VERSION ""

NS_ :

BS_:

BU_: Inverter

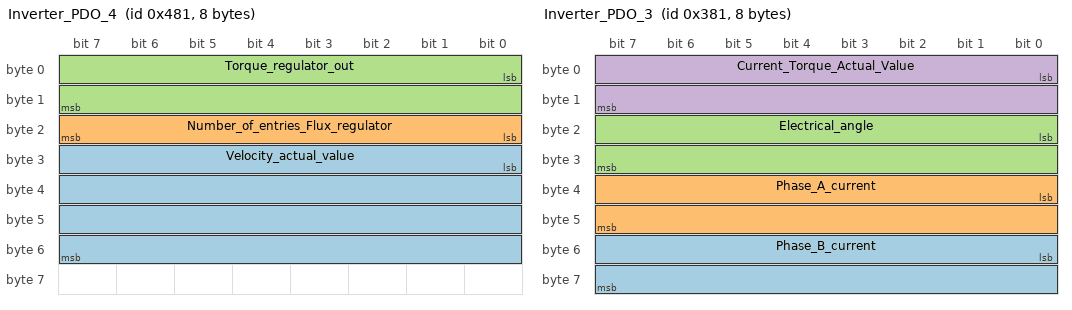
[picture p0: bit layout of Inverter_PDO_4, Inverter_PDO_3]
BO_ 1153 Inverter_PDO_4: 8 Vector__XXX
 SG_ Velocity_actual_value : 24|32@1- (1,0) [-2147483648|2147483647] "" Vector__XXX
 SG_ Number_of_entries_Flux_regulator : 16|8@1+ (1,0) [0|255] "" Vector__XXX
 SG_ Torque_regulator_out : 0|16@1- (1,0) [0|65535] "" Vector__XXX

BO_ 897 Inverter_PDO_3: 8 Vector__XXX
 SG_ Phase_B_current : 48|16@1- (1,0) [0|65535] "" Vector__XXX
 SG_ Phase_A_current : 32|16@1- (1,0) [0|65535] "" Vector__XXX
 SG_ Electrical_angle : 16|16@1- (1,0) [0|65535] "" Vector__XXX
 SG_ Current_Torque_Actual_Value : 0|16@1- (1,0) [0|65535] "" Vector__XXX

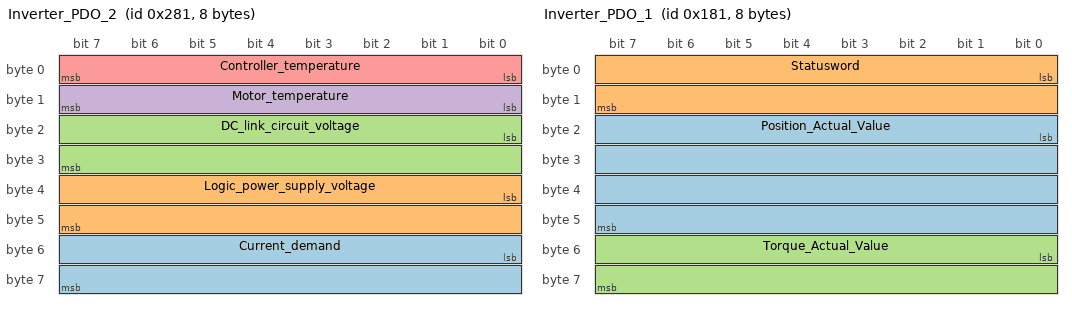
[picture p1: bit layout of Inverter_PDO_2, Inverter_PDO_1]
BO_ 641 Inverter_PDO_2: 8 Vector__XXX
 SG_ Current_demand : 48|16@1- (1,0) [0|65535] "" Vector__XXX
 SG_ Logic_power_supply_voltage : 32|16@1- (1,0) [0|65535] "" Vector__XXX
 SG_ DC_link_circuit_voltage : 16|16@1- (1,0) [0|65535] "" Vector__XXX
 SG_ Motor_temperature : 8|8@1+ (1,0) [0|255] "" Vector__XXX
 SG_ Controller_temperature : 0|8@1+ (1,0) [0|255] "" Vector__XXX

BO_ 385 Inverter_PDO_1: 8 Vector__XXX
 SG_ Position_Actual_Value : 16|32@1- (1,0) [0|0] "" Vector__XXX
 SG_ Statusword : 0|16@1+ (1,0) [0|100] "" Vector__XXX
 SG_ Torque_Actual_Value : 48|16@1- (0.001,0) [0|0] "Motor Nominal Current" Vector__XXX

BA_DEF_  "BusType" STRING ;
BA_DEF_DEF_  "BusType" "CAN";
